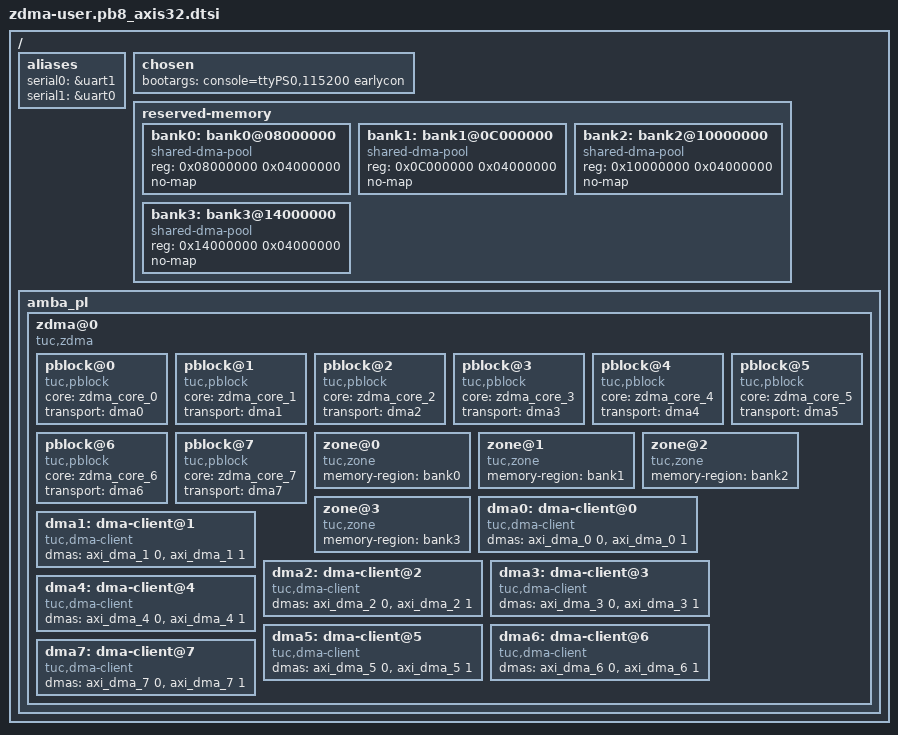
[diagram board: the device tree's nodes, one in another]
///include/ "system-conf.dtsi"
/  {
	aliases {
		serial0 = &uart1;
		serial1 = &uart0;
	};

	chosen {
		bootargs = "console=ttyPS0,115200 earlycon";
	};

	reserved-memory {
		#address-cells = <1>;
		#size-cells = <1>;
		ranges;
		
		bank0: bank0@08000000 {
			reg = <0x08000000 0x04000000>;
			compatible = "shared-dma-pool";
			no-map;
		};
		
		bank1: bank1@0C000000 {
			reg = <0x0C000000 0x04000000>;
			compatible = "shared-dma-pool";
			no-map;
		};
		bank2: bank2@10000000 {
			reg = <0x10000000 0x04000000>;
			compatible = "shared-dma-pool";
			no-map;
		};
		bank3: bank3@14000000 {
			reg = <0x14000000 0x04000000>;
			compatible = "shared-dma-pool";
			no-map;
		};
		
	};

	amba_pl {
		zdma@0 {
			compatible = "tuc,zdma";
			#address-cells = <1>;
			#size-cells = <1>;
			ranges;

			pblock@0 {
				compatible = "tuc,pblock";
				core = <&zdma_core_0>;
				transport = <&dma0>;
			};
			pblock@1 {
				compatible = "tuc,pblock";
				core = <&zdma_core_1>;
				transport = <&dma1>;
			};
			pblock@2 {
				compatible = "tuc,pblock";
				core = <&zdma_core_2>;
				transport = <&dma2>;
			};
			pblock@3 {
				compatible = "tuc,pblock";
				core = <&zdma_core_3>;
				transport = <&dma3>;
			};
			pblock@4 {
				compatible = "tuc,pblock";
				core = <&zdma_core_4>;
				transport = <&dma4>;
			};
			pblock@5 {
				compatible = "tuc,pblock";
				core = <&zdma_core_5>;
				transport = <&dma5>;
			};
			pblock@6 {
				compatible = "tuc,pblock";
				core = <&zdma_core_6>;
				transport = <&dma6>;
			};
			pblock@7 {
				compatible = "tuc,pblock";
				core = <&zdma_core_7>;
				transport = <&dma7>;
			};

			zone@0 {
				compatible = "tuc,zone";
				memory-region = <&bank0>;
			};
			zone@1 {
				compatible = "tuc,zone";
				memory-region = <&bank1>;
			};
			zone@2 {
				compatible = "tuc,zone";
				memory-region = <&bank2>;
			};
			zone@3 {
				compatible = "tuc,zone";
				memory-region = <&bank3>;
			};
			
			dma0: dma-client@0 {
				compatible = "tuc,dma-client";
				dmas = <&axi_dma_0 0
					&axi_dma_0 1>;
				dma-names = "tx", "rx";
			};
			dma1: dma-client@1 {
				compatible = "tuc,dma-client";
				dmas = <&axi_dma_1 0
					&axi_dma_1 1>;
				dma-names = "tx", "rx";
			};
			dma2: dma-client@2 {
				compatible = "tuc,dma-client";
				dmas = <&axi_dma_2 0
					&axi_dma_2 1>;
				dma-names = "tx", "rx";
			};
			dma3: dma-client@3 {
				compatible = "tuc,dma-client";
				dmas = <&axi_dma_3 0
					&axi_dma_3 1>;
				dma-names = "tx", "rx";
			};
			dma4: dma-client@4 {
				compatible = "tuc,dma-client";
				dmas = <&axi_dma_4 0
					&axi_dma_4 1>;
				dma-names = "tx", "rx";
			};
			dma5: dma-client@5 {
				compatible = "tuc,dma-client";
				dmas = <&axi_dma_5 0
					&axi_dma_5 1>;
				dma-names = "tx", "rx";
			};
			dma6: dma-client@6 {
				compatible = "tuc,dma-client";
				dmas = <&axi_dma_6 0
					&axi_dma_6 1>;
				dma-names = "tx", "rx";
			};
			dma7: dma-client@7 {
				compatible = "tuc,dma-client";
				dmas = <&axi_dma_7 0
					&axi_dma_7 1>;
				dma-names = "tx", "rx";
			};
		};
	};
};

